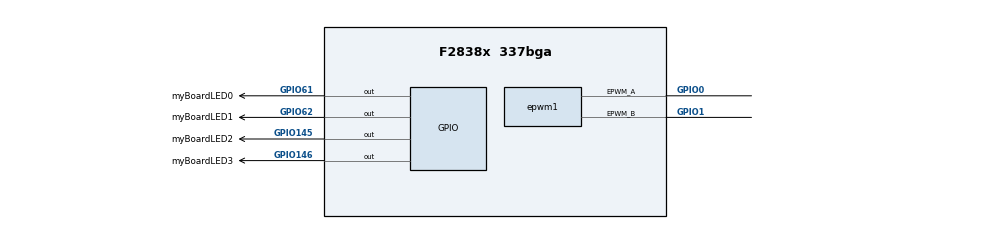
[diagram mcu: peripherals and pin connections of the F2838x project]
/**
 * @cliArgs --device "F2838x" --part "F2838x_337bga" --package "337bga" --context "CPU1" --product "C2000WARE@6.00.01.00"
 * @versions {"tool":"1.26.0+4407"}
 */

/**
 * Import the modules used in this configuration.
 */
const led       = scripting.addModule("/driverlib/board_components/led", {}, false);
const led1      = led.addInstance();
const led2      = led.addInstance();
const led3      = led.addInstance();
const led4      = led.addInstance();
const cputimer  = scripting.addModule("/driverlib/cputimer.js", {}, false);
const cputimer1 = cputimer.addInstance();
const cputimer2 = cputimer.addInstance();
const epwm      = scripting.addModule("/driverlib/epwm.js", {}, false);
const epwm1     = epwm.addInstance();

/**
 * Write custom configuration values to the imported modules.
 */
led1.$name                = "myBoardLED0";
led1.gpio.$name           = "LED1_61";
led1.gpio.gpioPin.$assign = "GPIO61";

led2.$name                = "myBoardLED1";
led2.gpio.$name           = "LED2_62";
led2.gpio.gpioPin.$assign = "GPIO62";

led3.$name                = "myBoardLED2";
led3.gpio.$name           = "LED3_145";
led3.gpio.gpioPin.$assign = "GPIO145";

led4.$name                = "myBoardLED3";
led4.gpio.$name           = "LED4_146";
led4.gpio.gpioPin.$assign = "GPIO146";

const divider3       = system.clockTree["AUX_REFDIV"];
divider3.divideValue = 1;

const divider10       = system.clockTree["EPWMCLKDIV"];
divider10.divideValue = 1;

const multiplier2         = system.clockTree["PLL_IMULT"];
multiplier2.multiplyValue = 80;

const mux1       = system.clockTree["AUXOSCCLKSRCSEL"];
mux1.inputSelect = "INTOSC2";

const mux15       = system.clockTree["OSCCLKSRCSEL"];
mux15.inputSelect = "INTOSC2";

cputimer1.$name                    = "myCPUTIMER0";
cputimer1.timerPeriod              = 199999999;
cputimer1.registerInterrupts       = true;
cputimer1.enableInterrupt          = true;
cputimer1.timerInt.enableInterrupt = true;

cputimer2.$name                    = "myCPUTIMER1";
cputimer2.cputimerBase             = "CPUTIMER1_BASE";
cputimer2.timerPeriod              = 99999999;
cputimer2.enableInterrupt          = true;
cputimer2.registerInterrupts       = true;
cputimer2.timerInt.enableInterrupt = true;

const default_warning = scripting.addModule("/driverlib/default_warning.js", {}, false);
scripting.suppress("Add the \'Device Support\' module in order to use Clock Tree tool and generate device support files\\. This suggestion can be ignored if not using the Clock Tree tool\\.", default_warning);

epwm1.epwmTimebase_clockDiv                                      = "EPWM_CLOCK_DIVIDER_4";
epwm1.epwmTimebase_hsClockDiv                                    = "EPWM_HSCLOCK_DIVIDER_4";
epwm1.epwmTimebase_period                                        = 2000;
epwm1.epwmTimebase_counterMode                                   = "EPWM_COUNTER_MODE_UP_DOWN";
epwm1.epwmCounterCompare_cmpA                                    = 500;
epwm1.epwmCounterCompare_cmpB                                    = 1500;
epwm1.epwmActionQualifier_EPWM_AQ_OUTPUT_A_ON_TIMEBASE_ZERO      = "EPWM_AQ_OUTPUT_LOW";
epwm1.epwmActionQualifier_EPWM_AQ_OUTPUT_A_ON_TIMEBASE_UP_CMPA   = "EPWM_AQ_OUTPUT_HIGH";
epwm1.epwmActionQualifier_EPWM_AQ_OUTPUT_A_ON_TIMEBASE_DOWN_CMPA = "EPWM_AQ_OUTPUT_LOW";
epwm1.epwmActionQualifier_EPWM_AQ_OUTPUT_B_ON_TIMEBASE_ZERO      = "EPWM_AQ_OUTPUT_LOW";
epwm1.epwmActionQualifier_EPWM_AQ_OUTPUT_B_ON_TIMEBASE_UP_CMPB   = "EPWM_AQ_OUTPUT_HIGH";
epwm1.epwmActionQualifier_EPWM_AQ_OUTPUT_B_ON_TIMEBASE_DOWN_CMPB = "EPWM_AQ_OUTPUT_LOW";
epwm1.$name                                                      = "EPWM1_U";
epwm1.epwm.$assign                                               = "EPWM1";
epwm1.epwm.epwm_aPin.$assign                                     = "GPIO0";
epwm1.epwm.epwm_bPin.$assign                                     = "GPIO1";
